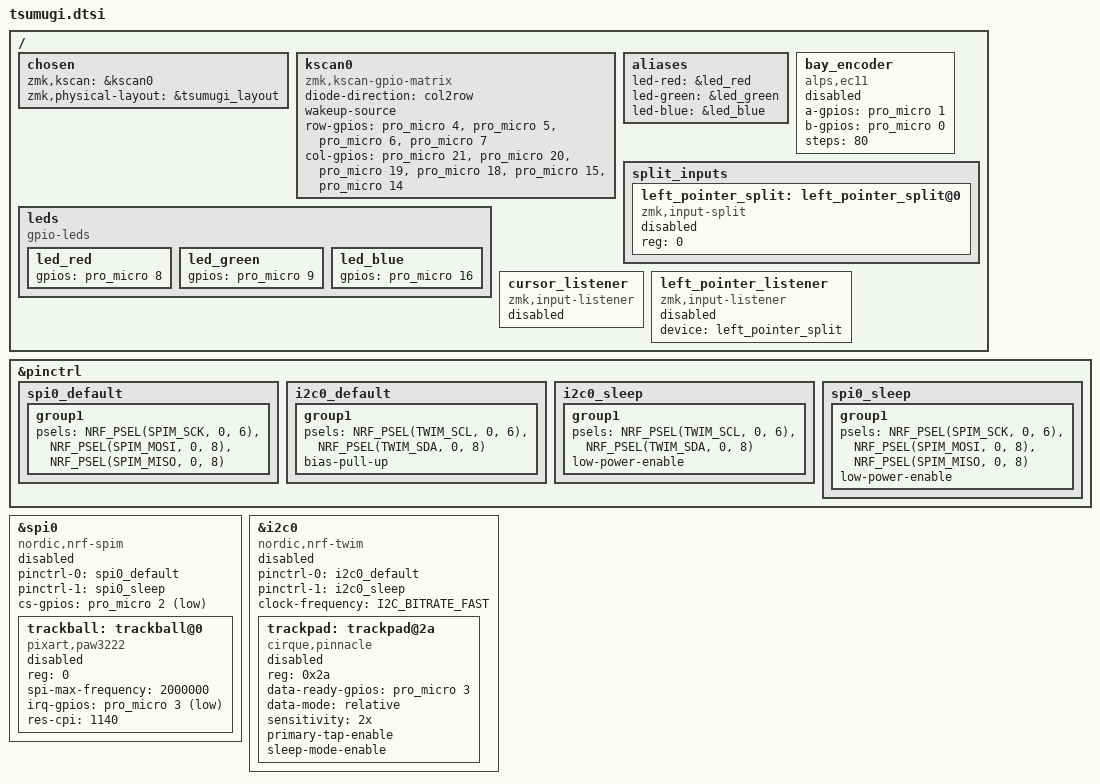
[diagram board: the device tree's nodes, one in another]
/*
 * Tsumugi - shared hardware description for both halves.
 *
 * Controller: nice!nano v2 / Pro Micro nRF52840 compatible (pro_micro nexus pins)
 *
 *   pro_micro | nRF   | function
 *   ----------+-------+-----------------------------------------------
 *      4      | P0.22 | ROW1        21 | P0.31 | COL1 (inner)
 *      5      | P0.24 | ROW2        20 | P0.29 | COL2
 *      6      | P1.00 | ROW3        19 | P0.02 | COL3
 *      7      | P0.11 | ROW4 thumb  18 | P1.15 | COL4
 *      1      | P0.06 | MOD SCK / ENC A   15 | P1.13 | COL5
 *      0      | P0.08 | MOD SDIO / ENC B  14 | P1.11 | COL6 (outer)
 *      2      | P0.17 | MOD NCS            8 | P1.04 | LED red
 *      3      | P0.20 | MOD MOTION         9 | P1.06 | LED green
 *     10      | P0.09 | AUX (spare pad)   16 | P0.10 | LED blue
 *
 * The module bay connector exposes GND, VCC (ext-power switched 3V3), the four
 * MOD lines and COL1 + a diode-protected ROW4 contact for a push switch.
 */

#include <dt-bindings/zmk/matrix_transform.h>
#include "tsumugi-layout.dtsi"

/ {
    chosen {
        zmk,kscan = &kscan0;
        zmk,physical-layout = &tsumugi_layout;
    };

    kscan0: kscan0 {
        compatible = "zmk,kscan-gpio-matrix";
        diode-direction = "col2row";
        wakeup-source;

        row-gpios
            = <&pro_micro 4 (GPIO_ACTIVE_HIGH | GPIO_PULL_DOWN)>
            , <&pro_micro 5 (GPIO_ACTIVE_HIGH | GPIO_PULL_DOWN)>
            , <&pro_micro 6 (GPIO_ACTIVE_HIGH | GPIO_PULL_DOWN)>
            , <&pro_micro 7 (GPIO_ACTIVE_HIGH | GPIO_PULL_DOWN)>
            ;

        col-gpios
            = <&pro_micro 21 GPIO_ACTIVE_HIGH>
            , <&pro_micro 20 GPIO_ACTIVE_HIGH>
            , <&pro_micro 19 GPIO_ACTIVE_HIGH>
            , <&pro_micro 18 GPIO_ACTIVE_HIGH>
            , <&pro_micro 15 GPIO_ACTIVE_HIGH>
            , <&pro_micro 14 GPIO_ACTIVE_HIGH>
            ;
    };

    /* status LED (light pipe next to the controller) - used by zmk-rgbled-widget */
    leds {
        compatible = "gpio-leds";
        led_red: led_red {
            gpios = <&pro_micro 8 GPIO_ACTIVE_HIGH>;
        };
        led_green: led_green {
            gpios = <&pro_micro 9 GPIO_ACTIVE_HIGH>;
        };
        led_blue: led_blue {
            gpios = <&pro_micro 16 GPIO_ACTIVE_HIGH>;
        };
    };

    aliases {
        led-red = &led_red;
        led-green = &led_green;
        led-blue = &led_blue;
    };

    /* module bay: EC11 rotary encoder (enabled by the tsumugi_encoder add-on) */
    bay_encoder: bay_encoder {
        compatible = "alps,ec11";
        a-gpios = <&pro_micro 1 (GPIO_ACTIVE_HIGH | GPIO_PULL_UP)>;
        b-gpios = <&pro_micro 0 (GPIO_ACTIVE_HIGH | GPIO_PULL_UP)>;
        steps = <80>;
        status = "disabled";
    };

    /* pointer (ball or trackpad) in the LEFT half's bay, forwarded over BLE */
    split_inputs {
        #address-cells = <1>;
        #size-cells = <0>;

        left_pointer_split: left_pointer_split@0 {
            compatible = "zmk,input-split";
            reg = <0>;
            status = "disabled";
        };
    };

    /* cursor pointer in the central's bay; the ball / trackpad add-on sets the device */
    cursor_listener: cursor_listener {
        compatible = "zmk,input-listener";
        status = "disabled";
    };

    left_pointer_listener: left_pointer_listener {
        compatible = "zmk,input-listener";
        status = "disabled";
        device = <&left_pointer_split>;
    };
};

/*
 * Module bay pointers. Only one of spi0 (ball) / i2c0 (trackpad) may be enabled:
 * they share the same nRF peripheral instance and the same two bay pins.
 */

/* module bay: PAW3222 optical sensor on a 3-wire SPI (SDIO on MOSI+MISO) */
&pinctrl {
    spi0_default: spi0_default {
        group1 {
            psels = <NRF_PSEL(SPIM_SCK, 0, 6)>,
                    <NRF_PSEL(SPIM_MOSI, 0, 8)>,
                    <NRF_PSEL(SPIM_MISO, 0, 8)>;
        };
    };

    i2c0_default: i2c0_default {
        group1 {
            psels = <NRF_PSEL(TWIM_SCL, 0, 6)>,
                    <NRF_PSEL(TWIM_SDA, 0, 8)>;
            bias-pull-up;
        };
    };

    i2c0_sleep: i2c0_sleep {
        group1 {
            psels = <NRF_PSEL(TWIM_SCL, 0, 6)>,
                    <NRF_PSEL(TWIM_SDA, 0, 8)>;
            low-power-enable;
        };
    };

    spi0_sleep: spi0_sleep {
        group1 {
            psels = <NRF_PSEL(SPIM_SCK, 0, 6)>,
                    <NRF_PSEL(SPIM_MOSI, 0, 8)>,
                    <NRF_PSEL(SPIM_MISO, 0, 8)>;
            low-power-enable;
        };
    };
};

&spi0 {
    compatible = "nordic,nrf-spim";
    pinctrl-0 = <&spi0_default>;
    pinctrl-1 = <&spi0_sleep>;
    pinctrl-names = "default", "sleep";
    cs-gpios = <&pro_micro 2 GPIO_ACTIVE_LOW>;
    status = "disabled";

    trackball: trackball@0 {
        compatible = "pixart,paw3222";
        reg = <0>;
        spi-max-frequency = <2000000>;
        irq-gpios = <&pro_micro 3 (GPIO_ACTIVE_LOW | GPIO_PULL_UP)>;
        res-cpi = <1140>;
        status = "disabled";
    };
};

/* module bay: Cirque Pinnacle 35 mm trackpad (TM035035) on I2C, DR on the MOTION pin */
&i2c0 {
    compatible = "nordic,nrf-twim";
    pinctrl-0 = <&i2c0_default>;
    pinctrl-1 = <&i2c0_sleep>;
    pinctrl-names = "default", "sleep";
    clock-frequency = <I2C_BITRATE_FAST>;
    status = "disabled";

    trackpad: trackpad@2a {
        compatible = "cirque,pinnacle";
        reg = <0x2a>;
        data-ready-gpios = <&pro_micro 3 GPIO_ACTIVE_HIGH>;
        data-mode = "relative";
        sensitivity = "2x";
        primary-tap-enable;
        sleep-mode-enable;
        status = "disabled";
    };
};
